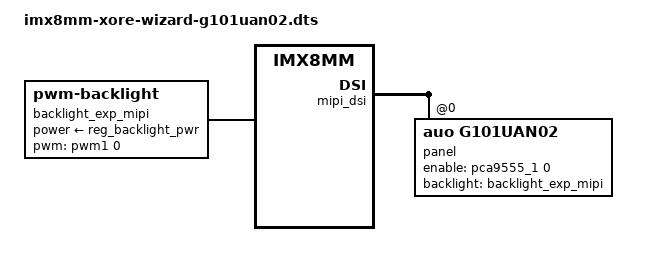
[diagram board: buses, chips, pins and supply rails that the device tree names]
/*
 * Copyright 2018 Technexion Ltd.
 * Copyright 2018 NXP
 *
 * Author: Richard Hu <richard.hu@technexion.com>
 *         Andy Lin <andy.lin@technexion.com>
 *
 * This program is free software; you can redistribute it and/or
 * modify it under the terms of the GNU General Public License
 * as published by the Free Software Foundation; either version 2
 * of the License, or (at your option) any later version.
 *
 * This program is distributed in the hope that it will be useful,
 * but WITHOUT ANY WARRANTY; without even the implied warranty of
 * MERCHANTABILITY or FITNESS FOR A PARTICULAR PURPOSE.  See the
 * GNU General Public License for more details.
 */

#include "imx8mm-xore-wizard.dts"

/ {
        backlight_exp_mipi: backlight_exp_mipi {
		compatible = "pwm-backlight";
		pwms = <&pwm1 0 50000 0>;
		brightness-levels = <0 36 72 108 144 180 216 255>;
		default-brightness-level = <6>;
		power-supply = <&reg_backlight_pwr>;
                status = "okay";
        };
};

&mipi_dsi {
        status = "okay";

        panel@0 {
                compatible = "auo,g101uan02";
                reg = <0>;
                pinctrl-0 = <&pinctrl_mipi_dsi_rst>;
                enable-gpios = <&pca9555_1 0 GPIO_ACTIVE_HIGH>;
                backlight = <&backlight_exp_mipi>;
                status = "okay";
        };
};
